VERSION ""

NS_ :

BS_:

BU_:

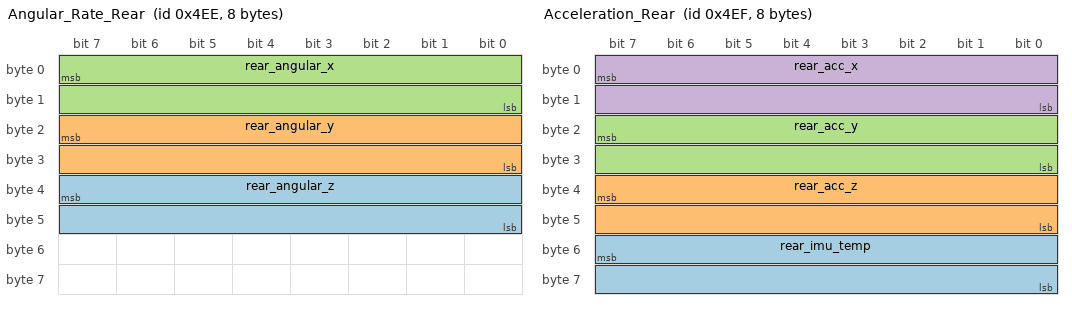
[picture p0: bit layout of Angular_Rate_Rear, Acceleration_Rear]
BO_ 1262 Angular_Rate_Rear: 8 Vector__XXX
 SG_ rear_angular_z : 39|16@0- (0.1,0) [-3276.8|3276.7] "deg/sec" Vector__XXX
 SG_ rear_angular_y : 23|16@0- (0.1,0) [-3276.8|3276.7] "deg/sec" Vector__XXX
 SG_ rear_angular_x : 7|16@0- (0.1,0) [-3276.8|3276.7] "deg/sec" Vector__XXX

BO_ 1263 Acceleration_Rear: 8 Vector__XXX
 SG_ rear_imu_temp : 55|16@0- (0.1,0) [-32768|32767] "C" Vector__XXX
 SG_ rear_acc_z : 39|16@0- (0.01,0) [-327.68|327.67] "g" Vector__XXX
 SG_ rear_acc_y : 23|16@0- (0.01,0) [-327.68|327.67] "g" Vector__XXX
 SG_ rear_acc_x : 7|16@0- (0.01,0) [-327.68|327.67] "g" Vector__XXX

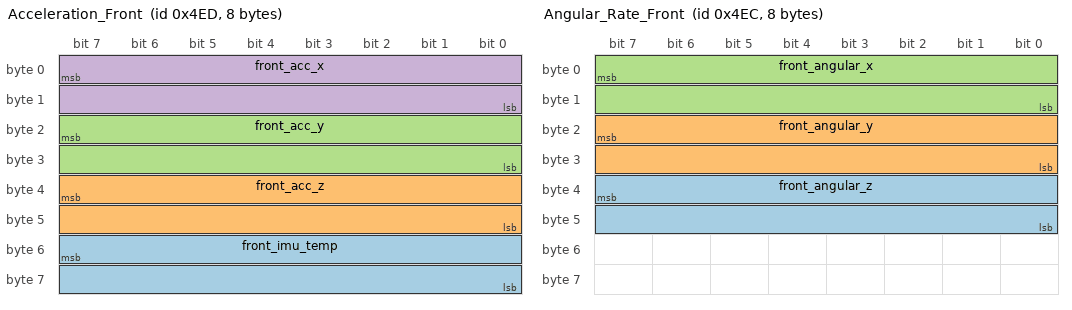
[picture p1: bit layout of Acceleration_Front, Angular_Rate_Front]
BO_ 1261 Acceleration_Front: 8 Vector__XXX
 SG_ front_imu_temp : 55|16@0- (0.1,0) [-32768|32767] "C" Vector__XXX
 SG_ front_acc_z : 39|16@0- (0.01,0) [-327.68|327.67] "g" Vector__XXX
 SG_ front_acc_y : 23|16@0- (0.01,0) [-327.68|327.67] "g" Vector__XXX
 SG_ front_acc_x : 7|16@0- (0.01,0) [-327.68|327.67] "g" Vector__XXX

BO_ 1260 Angular_Rate_Front: 8 Vector__XXX
 SG_ front_angular_z : 39|16@0- (0.1,0) [-3276.8|3276.7] "deg/sec" Vector__XXX
 SG_ front_angular_y : 23|16@0- (0.1,0) [-3276.8|3276.7] "deg/sec" Vector__XXX
 SG_ front_angular_x : 7|16@0- (0.1,0) [-3276.8|3276.7] "deg/sec" Vector__XXX

BA_DEF_ BO_  "GenMsgCycleTime" INT 0 0;
BA_DEF_DEF_  "GenMsgCycleTime" 0;
BA_ "GenMsgCycleTime" BO_ 1262 20;
BA_ "GenMsgCycleTime" BO_ 1263 20;
BA_ "GenMsgCycleTime" BO_ 1261 20;
BA_ "GenMsgCycleTime" BO_ 1260 20;
